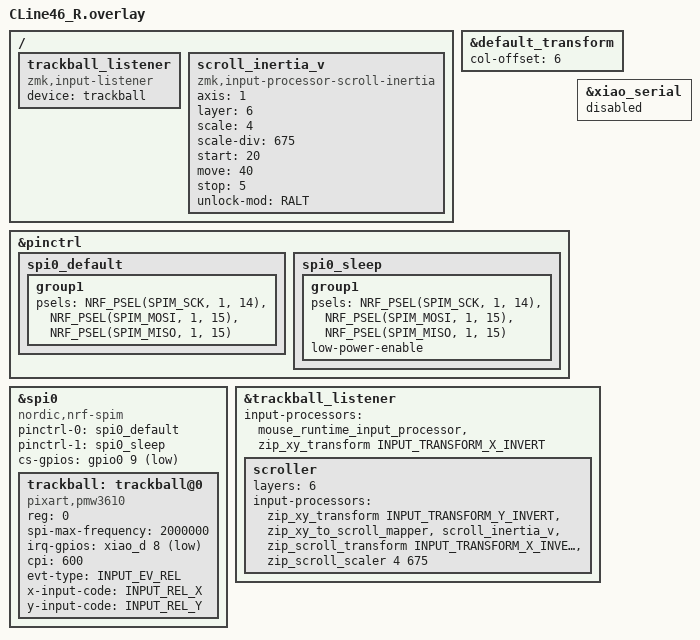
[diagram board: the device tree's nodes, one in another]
#include "CLine46.dtsi"
#include <zephyr/dt-bindings/input/input-event-codes.h>
#include <input/processors.dtsi>
#include <input/processors/runtime-input-processor.dtsi>
#include <behaviors/battery_history_request.dtsi>
#include <dt-bindings/zmk/modifiers.h>

&default_transform {
    col-offset = <6>;
};


/ {
    trackball_listener {
        status = "okay";
        compatible = "zmk,input-listener";
        device = <&trackball>;
    };

    // 慣性スクロールのノード定義
    scroll_inertia_v: scroll_inertia_v {
        compatible = "zmk,input-processor-scroll-inertia";
        #input-processor-cells = <0>;

        axis      = <1>;          // 1 = Y軸のみ（縦スクロールに制限）
        layer     = <6>;          // スクロールレイヤー番号と一致させる

        // 後段の zip_scroll_scaler の値と一致させる
        scale     = <4>;
        scale-div = <675>;

        start     = <20>;         // 慣性スクロールが開始する勢いの閾値
        move      = <40>;         // 慣性スクロールが開始するスクロール長さの閾値
        stop      = <5>;          // 慣性スクロールが停止する速度の閾値

        // オプション: Shiftを押している間だけ出力軸を反転
        // swap-mod  = <(MOD_LSFT|MOD_RSFT)>;

        // オプション: 右GUI（Winキー等）を押している間だけ両軸フリー（2Dスクロール）
        unlock-mod = <RALT>;
    };
};

&pinctrl {
    spi0_default: spi0_default {
        group1 {
            psels = <NRF_PSEL(SPIM_SCK, 1, 14)>,
                <NRF_PSEL(SPIM_MOSI, 1, 15)>,
                <NRF_PSEL(SPIM_MISO, 1, 15)>;
        };
    };

    spi0_sleep: spi0_sleep {
        group1 {
            psels = <NRF_PSEL(SPIM_SCK, 1, 14)>,
                <NRF_PSEL(SPIM_MOSI, 1, 15)>,
                <NRF_PSEL(SPIM_MISO, 1, 15)>;
            low-power-enable;
        };
    };
};


&xiao_serial { status = "disabled"; };

&spi0 {
    status = "okay";
    compatible = "nordic,nrf-spim";
    pinctrl-0 = <&spi0_default>;
    pinctrl-1 = <&spi0_sleep>;
    pinctrl-names = "default", "sleep";
    cs-gpios = <&gpio0 9 GPIO_ACTIVE_LOW>;  //P0.09を指定(CS)

    trackball: trackball@0 {
        status = "okay";
        compatible = "pixart,pmw3610";
        reg = <0>;
        spi-max-frequency = <2000000>;
        irq-gpios = <&xiao_d 8 (GPIO_ACTIVE_LOW | GPIO_PULL_UP)>;
        cpi = <600>;
        //swap-xy;
        evt-type = <INPUT_EV_REL>;
        x-input-code = <INPUT_REL_X>;
        y-input-code = <INPUT_REL_Y>;
    };
};

// Overrides for the input listener node
&trackball_listener {
    status = "okay";
    input-processors =<&mouse_runtime_input_processor>,
        //<&zip_xy_transform INPUT_TRANSFORM_Y_INVERT>;         //Y軸反転
        //<&zip_xy_transform INPUT_TRANSFORM_XY_SWAP>,        //X軸とY軸の入れ替え
        <&zip_xy_transform INPUT_TRANSFORM_X_INVERT>;       //X軸反転
        //<&zip_temp_layer 2 1000>;                            //オートマウスレイヤーの選択;


    scroller {
        layers = <6>;
        input-processors =
            // <&zip_xy_transform INPUT_TRANSFORM_XY_SWAP>,        //X軸とY軸の入れ替え
            // <&zip_xy_transform INPUT_TRANSFORM_X_INVERT>,       //X軸反転
            <&zip_xy_transform INPUT_TRANSFORM_Y_INVERT>,       //Y軸反転
            <&zip_xy_to_scroll_mapper>,                         //スクロールモードに変更

            // 慣性スクロールはスクロール量の倍率調整や軸の反転を行う前に適用したほうがよい（精度のため）
            <&scroll_inertia_v>,                                 //慣性スクロール
            <&zip_scroll_transform INPUT_TRANSFORM_X_INVERT>,   //スクロールのX軸反転
            //<&zip_scroll_transform INPUT_TRANSFORM_Y_INVERT>,   //スクロールのY軸反転
            <&zip_scroll_scaler 4 675>;                           //スクロール量を1/8倍
    };
};
